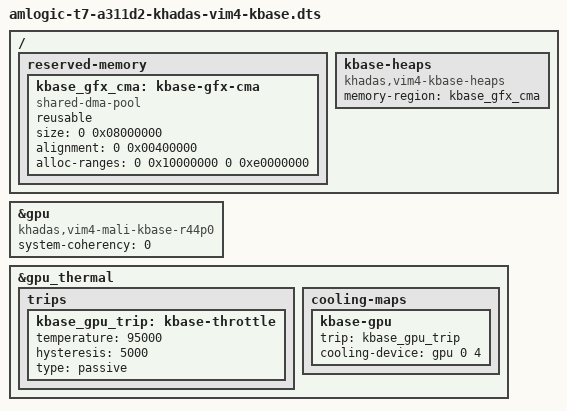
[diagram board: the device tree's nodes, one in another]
// SPDX-License-Identifier: GPL-2.0
/* Candidate only: preserve the display M0 profile and all its peripherals. */
#include "amlogic-t7-a311d2-khadas-vim4-display-m0.dts"

/ {
	reserved-memory {
		kbase_gfx_cma: kbase-gfx-cma {
			compatible = "shared-dma-pool";
			reusable;
			size = <0 0x08000000>;
			alignment = <0 0x00400000>;
			alloc-ranges = <0 0x10000000 0 0xe0000000>;
		};
	};

	kbase-heaps {
		compatible = "khadas,vim4-kbase-heaps";
		memory-region = <&kbase_gfx_cma>;
	};
};

&gpu {
	compatible = "khadas,vim4-mali-kbase-r44p0";
	/* Match the vendor DMA API maintenance and DDK ACE-Lite selection. */
	/delete-property/ dma-coherent;
	system-coherency = <0>;
	/* VDD_GPU stays at its existing always-on setting; no voltage scaling. */
	/delete-property/ mali-supply;
};

&gpu_thermal {
	trips {
		kbase_gpu_trip: kbase-throttle {
			temperature = <95000>;
			hysteresis = <5000>;
			type = "passive";
		};
	};
	cooling-maps {
		kbase-gpu {
			trip = <&kbase_gpu_trip>;
			cooling-device = <&gpu 0 4>;
		};
	};
};
